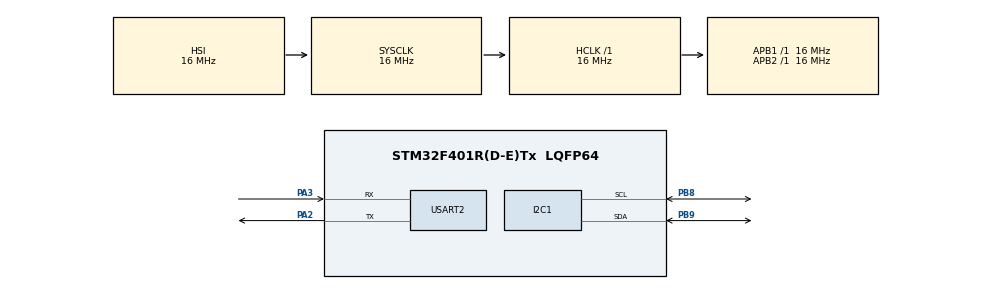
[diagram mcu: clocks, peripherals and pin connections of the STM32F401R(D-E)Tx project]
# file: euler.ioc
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Dma.I2C1_RX.0.Direction=DMA_PERIPH_TO_MEMORY
Dma.I2C1_RX.0.FIFOMode=DMA_FIFOMODE_DISABLE
Dma.I2C1_RX.0.Instance=DMA1_Stream0
Dma.I2C1_RX.0.MemDataAlignment=DMA_MDATAALIGN_BYTE
Dma.I2C1_RX.0.MemInc=DMA_MINC_ENABLE
Dma.I2C1_RX.0.Mode=DMA_NORMAL
Dma.I2C1_RX.0.PeriphDataAlignment=DMA_PDATAALIGN_BYTE
Dma.I2C1_RX.0.PeriphInc=DMA_PINC_DISABLE
Dma.I2C1_RX.0.Priority=DMA_PRIORITY_LOW
Dma.I2C1_TX.1.Direction=DMA_MEMORY_TO_PERIPH
Dma.I2C1_TX.1.FIFOMode=DMA_FIFOMODE_DISABLE
Dma.I2C1_TX.1.Instance=DMA1_Stream6
Dma.I2C1_TX.1.MemDataAlignment=DMA_MDATAALIGN_BYTE
Dma.I2C1_TX.1.MemInc=DMA_MINC_ENABLE
Dma.I2C1_TX.1.Mode=DMA_NORMAL
Dma.I2C1_TX.1.PeriphDataAlignment=DMA_PDATAALIGN_BYTE
Dma.I2C1_TX.1.PeriphInc=DMA_PINC_DISABLE
Dma.I2C1_TX.1.Priority=DMA_PRIORITY_LOW
Dma.Request0=I2C1_RX
Dma.Request1=I2C1_TX
Mcu.Family=STM32F4
Mcu.Name=STM32F401R(D-E)Tx
Mcu.Package=LQFP64
NVIC.DMA1_Stream0_IRQn=true\:0\:0\:false\:false\:true\:false\:true\:true
NVIC.DMA1_Stream6_IRQn=true\:0\:0\:false\:false\:true\:false\:true\:true
NVIC.PriorityGroup=NVIC_PRIORITYGROUP_4
PA2.Mode=Asynchronous
PA2.Signal=USART2_TX
PA3.Mode=Asynchronous
PA3.Signal=USART2_RX
PB8.Mode=I2C
PB8.Signal=I2C1_SCL
PB9.Mode=I2C
PB9.Signal=I2C1_SDA
ProjectManager.HeapSize=0x200
ProjectManager.StackSize=0x400
ProjectManager.TargetToolchain=STM32CubeIDE
RCC.AHBFreq_Value=16000000
RCC.APB1Freq_Value=16000000
RCC.APB2Freq_Value=16000000
RCC.CortexFreq_Value=16000000
RCC.HSE_VALUE=25000000
RCC.HSI_VALUE=16000000
RCC.LSE_VALUE=32768
RCC.SYSCLKFreq_VALUE=16000000
RCC.VCOOutputFreq_Value=192000000
USART2.VirtualMode=VM_ASYNC
board=custom

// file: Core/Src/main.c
/* USER CODE BEGIN Header */
/**
  ******************************************************************************
  * @file           : main.c
  * @brief          : Main program body
  ******************************************************************************
  * @attention
  *
  * Copyright (c) 2024 STMicroelectronics.
  * All rights reserved.
  *
  * This software is licensed under terms that can be found in the LICENSE file
  * in the root directory of this software component.
  * If no LICENSE file comes with this software, it is provided AS-IS.
  *
  ******************************************************************************
  */
/* USER CODE END Header */
#include "main.h"
#include "dma.h"
#include "i2c.h"
#include "usart.h"
#include "gpio.h"

/* USER CODE BEGIN Includes */
#include "bno055.h"
#include "string.h"
#include <stdio.h>
/* USER CODE END Includes */

void SystemClock_Config(void);

int main(void)
{
  /* USER CODE BEGIN 1 */
	uint8_t uartBuf[100];
	float		yaw, roll, pitch;
	uint8_t		imu_readings[IMU_NUMBER_OF_BYTES]; // read 6 bytes
	int16_t 	euler_data[3];
  /* USER CODE END 1 */

  /* MCU Configuration--------------------------------------------------------*/

  /* Reset of all peripherals, Initializes the Flash interface and the Systick. */
  HAL_Init();

  /* Configure the system clock */
  SystemClock_Config();

  /* Initialize all configured peripherals */
  MX_GPIO_Init();
  MX_DMA_Init();
  MX_I2C1_Init();
  MX_USART2_UART_Init();
  /* USER CODE BEGIN 2 */
  BNO055_Init_DNOF(&hi2c1);
  strcpy((char*)uartBuf, "hello program is starting\r\n");
  HAL_UART_Transmit(&huart2, uartBuf, strlen((char*)uartBuf) , 100);
  /* USER CODE END 2 */

  /* Infinite loop */
  while (1)
  {
	  HAL_Delay(300);
	  GetEulerData(&hi2c1, (uint8_t*)imu_readings);
	  euler_data[0] = (((int16_t)((uint8_t *)(imu_readings))[1] << 8) | ((uint8_t *)(imu_readings))[0]);
	  euler_data[1] = (((int16_t)((uint8_t *)(imu_readings))[3] << 8) | ((uint8_t *)(imu_readings))[2]);
	  euler_data[2] = (((int16_t)((uint8_t *)(imu_readings))[5] << 8) | ((uint8_t *)(imu_readings))[4]);

	  yaw = ((float)(euler_data[0]))/16.0f; //degrees
	  roll = ((float)(euler_data[1]))/16.0f;
	  pitch = ((float)(euler_data[2]))/16.0f;

	  sprintf((char*)uartBuf,"yaw: %.2f roll: %.2f pitch: %.2f\r\n", yaw, roll, pitch);
	  HAL_UART_Transmit(&huart2, uartBuf, strlen((char*)uartBuf), 1000);

  }
}

void SystemClock_Config(void)
{
  RCC_OscInitTypeDef RCC_OscInitStruct = {0};
  RCC_ClkInitTypeDef RCC_ClkInitStruct = {0};

  /** Configure the main internal regulator output voltage
  */
  __HAL_RCC_PWR_CLK_ENABLE();
  __HAL_PWR_VOLTAGESCALING_CONFIG(PWR_REGULATOR_VOLTAGE_SCALE2);

  /** Initializes the RCC Oscillators according to the specified parameters
  * in the RCC_OscInitTypeDef structure.
  */
  RCC_OscInitStruct.OscillatorType = RCC_OSCILLATORTYPE_HSI;
  RCC_OscInitStruct.HSIState = RCC_HSI_ON;
  RCC_OscInitStruct.HSICalibrationValue = RCC_HSICALIBRATION_DEFAULT;
  RCC_OscInitStruct.PLL.PLLState = RCC_PLL_NONE;
  if (HAL_RCC_OscConfig(&RCC_OscInitStruct) != HAL_OK)
  {
    Error_Handler();
  }

  /** Initializes the CPU, AHB and APB buses clocks
  */
  RCC_ClkInitStruct.ClockType = RCC_CLOCKTYPE_HCLK|RCC_CLOCKTYPE_SYSCLK
                              |RCC_CLOCKTYPE_PCLK1|RCC_CLOCKTYPE_PCLK2;
  RCC_ClkInitStruct.SYSCLKSource = RCC_SYSCLKSOURCE_HSI;
  RCC_ClkInitStruct.AHBCLKDivider = RCC_SYSCLK_DIV1;
  RCC_ClkInitStruct.APB1CLKDivider = RCC_HCLK_DIV1;
  RCC_ClkInitStruct.APB2CLKDivider = RCC_HCLK_DIV1;

  if (HAL_RCC_ClockConfig(&RCC_ClkInitStruct, FLASH_LATENCY_0) != HAL_OK)
  {
    Error_Handler();
  }
}

void Error_Handler(void)
{
  __disable_irq();
  while (1)
  {
  }
}
